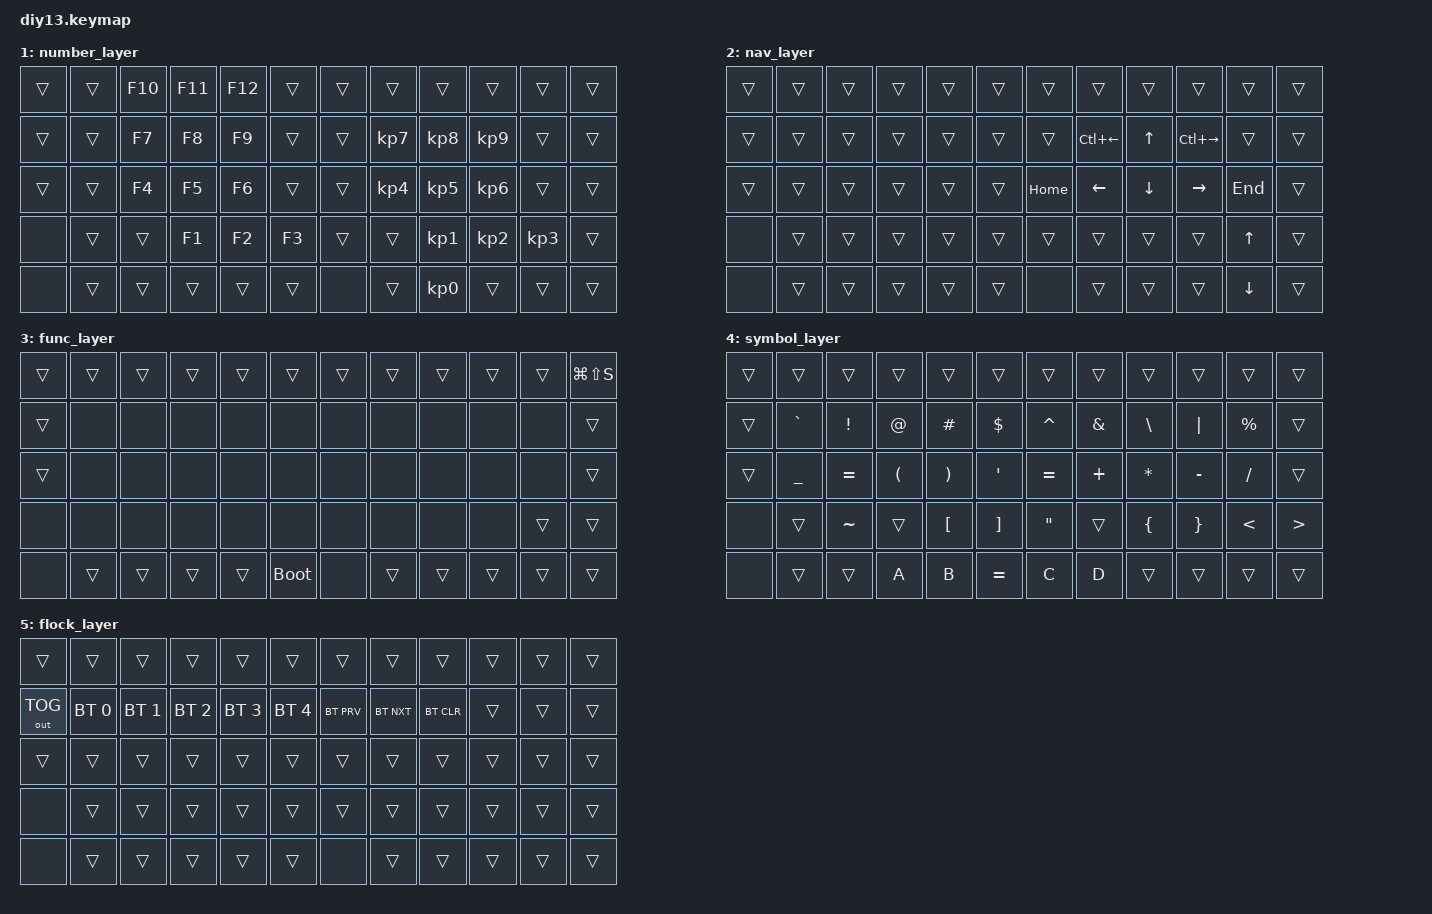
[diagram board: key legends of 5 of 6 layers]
#include <behaviors.dtsi>
#include <dt-bindings/zmk/bt.h>
#include <dt-bindings/zmk/keys.h>
#include <dt-bindings/zmk/outputs.h>

#define QUICK_TAP_MS 175

&lt {
    flavor = "balanced";
    tapping-term-ms = <200>;
    quick-tap-ms = <QUICK_TAP_MS>;
};

/ {
    behaviors {
        hm: home_row {
            compatible = "zmk,behavior-hold-tap";
            label = "HOME_ROW";
            bindings = <&kp>, <&kp>;

            #binding-cells = <2>;
            tapping-term-ms = <200>;
            quick-tap-ms = <QUICK_TAP_MS>;
            require-prior-idle-ms = <150>;
            flavor = "balanced";
            hold-trigger-key-positions = <25 26 27 28 31 32>;
            hold-trigger-on-release;
        };
    };

    keymap {
        compatible = "zmk,keymap";

        default_layer {
            bindings = <
&kp ESC    &kp N1          &kp N2          &kp N3            &kp N4       &kp N5      &kp N6  &kp N7            &kp N8            &kp N9           &kp N0           &kp BSPC
&kp TAB    &kp Q           &kp W           &kp E             &kp R        &kp T       &kp Y   &kp U             &kp I             &kp O            &kp P            &kp BSLH
&kp LCTRL  &hm LEFT_GUI A  &hm LEFT_ALT S  &hm LEFT_SHIFT D  &hm LCTRL F  &kp G       &kp H   &hm LCTRL J       &hm LEFT_SHIFT K  &kp L            &kp SEMI         &kp SQT
      &kp LSHFT       &kp Z           &kp X             &kp C        &kp V       &kp B   &kp N             &kp M             &kp COMMA        &kp DOT          &kp FSLH
&kp LEFT_GUI    &kp C_VOL_DN    &kp C_VOLUME_UP   &lt 1 DEL    &lt 2 BSPC    &lt 3 ENTER       &lt 4 SPACE       &lt 2 RIGHT_ALT  &kp LEFT         &kp RIGHT
            >;
        };

        number_layer {
            bindings = <
&trans     &trans          &kp F10         &kp F11           &kp F12      &trans      &trans     &trans            &trans            &trans           &trans            &trans
&trans     &trans          &kp F7          &kp F8            &kp F9       &trans      &trans     &kp KP_NUMBER_7   &kp KP_NUMBER_8   &kp KP_NUMBER_9  &trans            &trans
&trans     &trans          &kp F4          &kp F5            &kp F6       &trans      &trans     &kp KP_NUMBER_4   &kp KP_NUMBER_5   &kp KP_NUMBER_6  &trans            &trans
&none      &trans          &trans          &kp F1            &kp F2       &kp F3      &trans     &trans            &kp KP_NUMBER_1   &kp KP_NUMBER_2  &kp KP_NUMBER_3   &trans
&none      &trans          &trans          &trans            &trans       &trans      &none      &trans            &kp KP_NUMBER_0   &trans           &trans            &trans
            >;
        };

        nav_layer {
            bindings = <
&trans      &trans         &trans          &trans            &trans       &trans      &trans    &trans            &trans            &trans           &trans           &trans
&trans      &trans         &trans          &trans            &trans       &trans      &trans    &kp LC(LEFT)      &kp UP_ARROW      &kp LC(RIGHT)    &trans           &trans
&trans      &trans         &trans          &trans            &trans       &trans      &kp HOME  &kp LEFT          &kp DOWN          &kp RIGHT        &kp END          &trans
&none       &trans         &trans          &trans            &trans       &trans      &trans    &trans            &trans            &trans           &kp UP           &trans
&none       &trans         &trans          &trans            &trans       &trans      &none     &trans            &trans            &trans           &kp DOWN         &trans
            >;
        };

        func_layer {
            bindings = <
&trans  &trans  &trans  &trans  &trans  &trans       &trans  &trans  &trans  &trans  &trans  &kp LG(LS(S))
&trans  &none   &none   &none   &none   &none        &none   &none   &none   &none   &none   &trans
&trans  &none   &none   &none   &none   &none        &none   &none   &none   &none   &none   &trans
&none   &none   &none   &none   &none   &none        &none   &none   &none   &none   &trans  &trans
&none   &trans  &trans  &trans  &trans  &bootloader  &none   &trans  &trans  &trans  &trans  &trans
            >;
        };

        symbol_layer {
            bindings = <
&trans  &trans     &trans     &trans    &trans    &trans     &trans     &trans    &trans     &trans     &trans     &trans
&trans  &kp GRAVE  &kp EXCL   &kp AT    &kp HASH  &kp DLLR   &kp CARET  &kp AMPS  &kp BSLH   &kp PIPE   &kp PRCNT  &trans
&trans  &kp UNDER  &kp EQUAL  &kp LPAR  &kp RPAR  &kp APOS   &kp EQUAL  &kp PLUS  &kp ASTRK  &kp MINUS  &kp SLASH  &trans
&none   &trans     &kp TILDE  &trans    &kp LBKT  &kp RBKT   &kp DQT    &trans    &kp LBRC   &kp RBRC   &kp LT     &kp GT
&none   &trans     &trans     &kp A     &kp B     &kp EQUAL  &kp C      &kp D     &trans     &trans     &trans     &trans
            >;
        };

        flock_layer {
            bindings = <
&trans        &trans        &trans        &trans        &trans        &trans        &trans      &trans      &trans      &trans  &trans  &trans
&out OUT_TOG  &bt BT_SEL 0  &bt BT_SEL 1  &bt BT_SEL 2  &bt BT_SEL 3  &bt BT_SEL 4  &bt BT_PRV  &bt BT_NXT  &bt BT_CLR  &trans  &trans  &trans
&trans        &trans        &trans        &trans        &trans        &trans        &trans      &trans      &trans      &trans  &trans  &trans
&none         &trans        &trans        &trans        &trans        &trans        &trans      &trans      &trans      &trans  &trans  &trans
&none         &trans        &trans        &trans        &trans        &trans        &none       &trans      &trans      &trans  &trans  &trans
            >;
        };
    };
};
